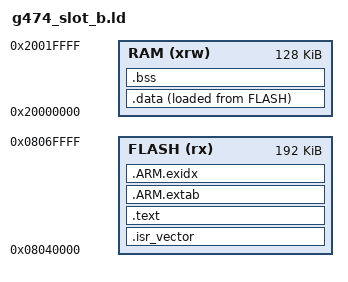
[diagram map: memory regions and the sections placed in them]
ENTRY(Reset_Handler)

MEMORY
{
  FLASH (rx) : ORIGIN = 0x08040000, LENGTH = 192K
  RAM (xrw)  : ORIGIN = 0x20000000, LENGTH = 128K
}

_estack = ORIGIN(RAM) + LENGTH(RAM);

SECTIONS
{
  .isr_vector :
  {
    KEEP(*(.isr_vector))
  } > FLASH

  .text :
  {
    *(.text*)
    *(.rodata*)
    *(.glue_7)
    *(.glue_7t)
    *(.eh_frame)
  } > FLASH

  .ARM.extab :
  {
    *(.ARM.extab*)
  } > FLASH

  .ARM.exidx :
  {
    *(.ARM.exidx*)
  } > FLASH

  _sidata = LOADADDR(.data);
  .data :
  {
    _sdata = .;
    *(.data*)
    _edata = .;
  } > RAM AT > FLASH

  .bss :
  {
    _sbss = .;
    *(.bss*)
    *(COMMON)
    _ebss = .;
  } > RAM
}
